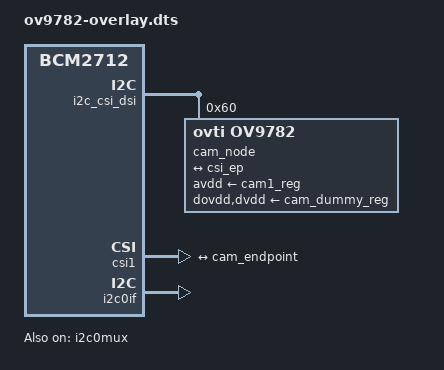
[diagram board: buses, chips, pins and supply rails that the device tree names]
// SPDX-License-Identifier: GPL-2.0-only
// Raspberry Pi camera overlay for OmniVision OV9782 on CSI connector
/dts-v1/;
/plugin/;

/{
	compatible = "brcm,bcm2712";

	i2c_frag: fragment@0 {
		target = <&i2c_csi_dsi>;
		__overlay__ {
			#address-cells = <1>;
			#size-cells = <0>;
			status = "okay";

			cam_node: ov9782@60 {
				compatible = "ovti,ov9782";
				reg = <0x60>;
				status = "disabled";

				clocks = <&cam1_clk>;
				clock-names = "xvclk";

				avdd-supply = <&cam1_reg>;
				dovdd-supply = <&cam_dummy_reg>;
				dvdd-supply = <&cam_dummy_reg>;

				rotation = <0>;
				orientation = <2>;

				port {
					cam_endpoint: endpoint {
						clock-lanes = <0>;
						data-lanes = <1 2>;
						link-frequencies = /bits/ 64 <400000000>;
					};
				};
			};
		};
	};

	csi_frag: fragment@1 {
		target = <&csi1>;
		csi: __overlay__ {
			status = "okay";

			port {
				csi_ep: endpoint {
					remote-endpoint = <&cam_endpoint>;
					data-lanes = <1 2>;
				};
			};
		};
	};

	fragment@2 {
		target = <&i2c0if>;
		__overlay__ {
			status = "okay";
		};
	};

	fragment@3 {
		target = <&i2c0mux>;
		__overlay__ {
			status = "okay";
		};
	};

	clk_frag: fragment@4 {
		target = <&cam1_clk>;
		__overlay__ {
			status = "okay";
			clock-frequency = <24000000>;
		};
	};

	fragment@5 {
		target = <&csi1>;
		__dormant__ {
			compatible = "brcm,bcm2835-unicam-legacy";
		};
	};

	reg_frag: fragment@6 {
		target = <&cam1_reg>;
		__dormant__ {
			startup-delay-us = <20000>;
			off-on-delay-us = <30000>;
		};
	};

	fragment@7 {
		target = <&csi_ep>;
		__overlay__ {
			clock-noncontinuous;
		};
	};

	fragment@8 {
		target = <&cam_endpoint>;
		__overlay__ {
			clock-noncontinuous;
		};
	};

	__overrides__ {
		rotation = <&cam_node>,"rotation:0";
		orientation = <&cam_node>,"orientation:0";
		media-controller = <0>,"!5";
		cam0 = <&i2c_frag>, "target:0=",<&i2c_csi_dsi0>,
		       <&csi_frag>, "target:0=",<&csi0>,
		       <&clk_frag>, "target:0=",<&cam0_clk>,
		       <&cam_node>, "clocks:0=",<&cam0_clk>,
		       <&cam_node>, "avdd-supply:0=",<&cam0_reg>,
		       <&reg_frag>, "target:0=",<&cam0_reg>;
		cam1 = <&i2c_frag>, "target:0=",<&i2c_csi_dsi1>,
		       <&csi_frag>, "target:0=",<&csi1>,
		       <&clk_frag>, "target:0=",<&cam1_clk>,
		       <&cam_node>, "clocks:0=",<&cam1_clk>,
		       <&cam_node>, "avdd-supply:0=",<&cam1_reg>,
		       <&reg_frag>, "target:0=",<&cam1_reg>;
		clk-continuous = <0>, "-7-8";
	};
};

&cam_node {
	status = "okay";
};

&cam_endpoint {
	remote-endpoint = <&csi_ep>;
};
